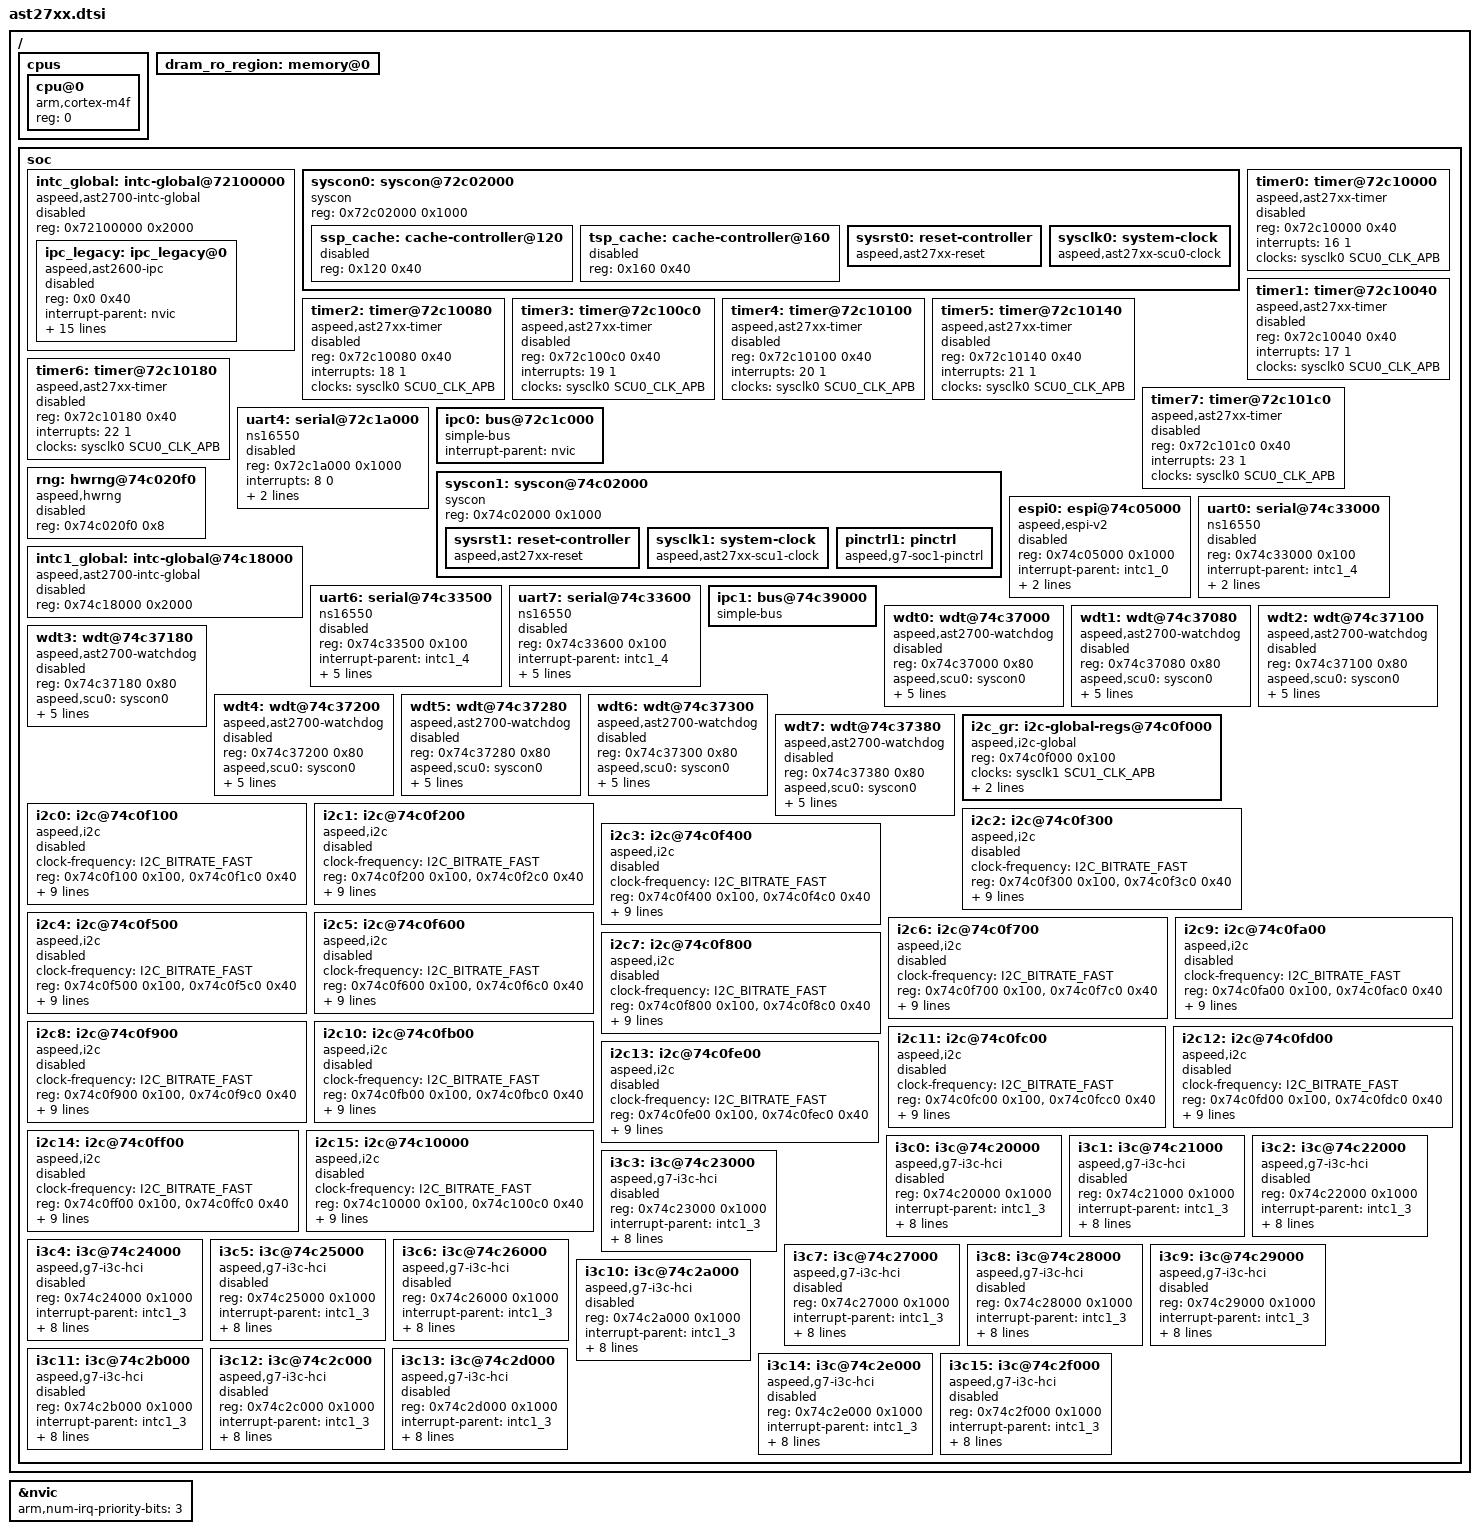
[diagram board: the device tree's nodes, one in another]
/*
 * SPDX-License-Identifier: Apache-2.0
 *
 * Copyright (c) 2023 ASPEED Technology Inc.
 */

#include <arm/armv7-m.dtsi>
#include <mem.h>
#include <aspeed/ast10x0-irq.h>
#include <zephyr/dt-bindings/clock/ast27xx_clock.h>
#include <zephyr/dt-bindings/reset/ast27xx_reset.h>
#include <zephyr/dt-bindings/i2c/i2c.h>
#include <zephyr/dt-bindings/pinctrl/ast27xx-soc1-pinctrl-groups.h>

/ {
	cpus {
		#address-cells = <1>;
		#size-cells = <0>;

		cpu@0 {
			device_type = "cpu";
			compatible = "arm,cortex-m4f";
			reg = <0>;
		};
	};

	dram_ro_region: memory@0 {
		device_type = "memory";
	};

	soc {
		intc_global: intc-global@72100000 {
			compatible = "aspeed,ast2700-intc-global", "syscon";
			reg = <0x72100000 0x2000>;
			#global-reg-cells = <2>;
			#address-cells = <1>;
			#size-cells = <1>;
			status = "disabled";

			ipc_legacy: ipc_legacy@0 {
				compatible = "aspeed,ast2600-ipc";
				reg = <0x0 0x40>;
				interrupt-parent = <&nvic>;
				interrupts = <144 AST10X0_IRQ_DEFAULT_PRIORITY>,
							 <145 AST10X0_IRQ_DEFAULT_PRIORITY>,
							 <146 AST10X0_IRQ_DEFAULT_PRIORITY>,
							 <147 AST10X0_IRQ_DEFAULT_PRIORITY>,
							 <148 AST10X0_IRQ_DEFAULT_PRIORITY>,
							 <149 AST10X0_IRQ_DEFAULT_PRIORITY>,
							 <150 AST10X0_IRQ_DEFAULT_PRIORITY>,
							 <151 AST10X0_IRQ_DEFAULT_PRIORITY>,
							 <152 AST10X0_IRQ_DEFAULT_PRIORITY>,
							 <153 AST10X0_IRQ_DEFAULT_PRIORITY>,
							 <154 AST10X0_IRQ_DEFAULT_PRIORITY>,
							 <155 AST10X0_IRQ_DEFAULT_PRIORITY>,
							 <156 AST10X0_IRQ_DEFAULT_PRIORITY>,
							 <157 AST10X0_IRQ_DEFAULT_PRIORITY>,
							 <158 AST10X0_IRQ_DEFAULT_PRIORITY>;
				status = "disabled";
			};
		};

		syscon0: syscon@72c02000 {
			compatible = "syscon";
			reg = <0x72c02000 0x1000>;
			#address-cells = <1>;
			#size-cells = <1>;
			ranges;

			ssp_cache: cache-controller@120 {
				reg = <0x120 0x40>;
				status = "disabled";
			};

			tsp_cache: cache-controller@160 {
				reg = <0x160 0x40>;
				status = "disabled";
			};

			sysrst0: reset-controller {
				compatible = "aspeed,ast27xx-reset";
				#reset-cells = <1>;
			};

			sysclk0: system-clock {
				compatible = "aspeed,ast27xx-scu0-clock";
				#clock-cells = <1>;
			};
		};

		timer0: timer@72c10000 {
			compatible = "aspeed,ast27xx-timer";
			reg = <0x72c10000 0x40>;
			interrupts = <16 1>;
			clocks = <&sysclk0 SCU0_CLK_APB>;
			status = "disabled";
		};

		timer1: timer@72c10040 {
			compatible = "aspeed,ast27xx-timer";
			reg = <0x72c10040 0x40>;
			interrupts = <17 1>;
			clocks = <&sysclk0 SCU0_CLK_APB>;
			status = "disabled";
		};

		timer2: timer@72c10080 {
			compatible = "aspeed,ast27xx-timer";
			reg = <0x72c10080 0x40>;
			interrupts = <18 1>;
			clocks = <&sysclk0 SCU0_CLK_APB>;
			status = "disabled";
		};

		timer3: timer@72c100c0 {
			compatible = "aspeed,ast27xx-timer";
			reg = <0x72c100c0 0x40>;
			interrupts = <19 1>;
			clocks = <&sysclk0 SCU0_CLK_APB>;
			status = "disabled";
		};

		timer4: timer@72c10100 {
			compatible = "aspeed,ast27xx-timer";
			reg = <0x72c10100 0x40>;
			interrupts = <20 1>;
			clocks = <&sysclk0 SCU0_CLK_APB>;
			status = "disabled";
		};

		timer5: timer@72c10140 {
			compatible = "aspeed,ast27xx-timer";
			reg = <0x72c10140 0x40>;
			interrupts = <21 1>;
			clocks = <&sysclk0 SCU0_CLK_APB>;
			status = "disabled";
		};

		timer6: timer@72c10180 {
			compatible = "aspeed,ast27xx-timer";
			reg = <0x72c10180 0x40>;
			interrupts = <22 1>;
			clocks = <&sysclk0 SCU0_CLK_APB>;
			status = "disabled";
		};

		timer7: timer@72c101c0 {
			compatible = "aspeed,ast27xx-timer";
			reg = <0x72c101c0 0x40>;
			interrupts = <23 1>;
			clocks = <&sysclk0 SCU0_CLK_APB>;
			status = "disabled";
		};

		uart4: serial@72c1a000 {
			compatible = "ns16550";
			reg = <0x72c1a000 0x1000>;
			interrupts = <8 0>;
			clocks = <&sysclk0 SCU0_CLK_GATE_UART4CLK>;
			status = "disabled";
			reg-shift = <2>;
		};

		ipc0: bus@72c1c000 {
			#address-cells = <1>;
			#size-cells = <1>;
			compatible = "simple-bus";
			interrupt-parent = <&nvic>;
			ranges = <0 0x72c1c000 0x1000>;
		};

		syscon1: syscon@74c02000 {
			compatible = "syscon";
			reg = <0x74c02000 0x1000>;
			#address-cells = <1>;
			#size-cells = <1>;
			ranges;

			sysrst1: reset-controller {
				compatible = "aspeed,ast27xx-reset";
				#reset-cells = <1>;
			};

			sysclk1: system-clock {
				compatible = "aspeed,ast27xx-scu1-clock";
				#clock-cells = <1>;
			};

			pinctrl1: pinctrl {
				compatible = "aspeed,g7-soc1-pinctrl";
			};
		};

		rng: hwrng@74c020f0 {
			compatible = "aspeed,hwrng";
			reg = <0x74c020f0 0x8>;
			status = "disabled";
		};

		espi0: espi@74c05000 {
			compatible = "aspeed,espi-v2";
			reg = <0x74c05000 0x1000>;
			interrupt-parent = <&intc1_0>;
			interrupts = <10 1>;
			clocks = <&sysclk1 SCU1_CLK_GATE_ESPI0CLK>;
			status = "disabled";
		};

		intc1_global: intc-global@74c18000 {
			compatible = "aspeed,ast2700-intc-global", "syscon";
			reg = <0x74c18000 0x2000>;
			#global-reg-cells = <2>;
			#address-cells = <1>;
			#size-cells = <1>;
			status = "disabled";
		};

		uart0: serial@74c33000 {
			compatible = "ns16550";
			reg = <0x74c33000 0x100>;
			interrupt-parent = <&intc1_4>;
			interrupts = <7 1>;
			status = "disabled";
			reg-shift = <2>;
		};

		uart6: serial@74c33500 {
			compatible = "ns16550";
			reg = <0x74c33500 0x100>;
			interrupt-parent = <&intc1_4>;
			interrupts = <12 1>;
			clocks = <&sysclk1 SCU1_CLK_GATE_UART6CLK>;
			resets = <&sysrst1 SCU1_RESET_UART6>;
			pinctrl-names = "default";
			pinctrl-0 = <pinctrl_uart6_default>;
			status = "disabled";
			reg-shift = <2>;
		};

		uart7: serial@74c33600 {
			compatible = "ns16550";
			reg = <0x74c33600 0x100>;
			interrupt-parent = <&intc1_4>;
			interrupts = <13 1>;
			clocks = <&sysclk1 SCU1_CLK_GATE_UART7CLK>;
			resets = <&sysrst1 SCU1_RESET_UART7>;
			pinctrl-names = "default";
			pinctrl-0 = <pinctrl_uart7_default>;
			status = "disabled";
			reg-shift = <2>;
		};

		ipc1: bus@74c39000 {
			#address-cells = <1>;
			#size-cells = <1>;
			compatible = "simple-bus";
			ranges = <0 0x74c39000 0x1000>;
		};

		wdt0: wdt@74c37000 {
			compatible = "aspeed,ast2700-watchdog";
			reg = <0x74c37000 0x80>;
			aspeed,scu0 = <&syscon0>;
			aspeed,scu1 = <&syscon1>;
			interrupt-parent = <&intc1_3>;
			interrupts = <16 1>;
			reset-mask = <0x8207ff79 0x000003f6 0x000093ec 0x40303803 0x00320000>;
			status = "disabled";
		};

		wdt1: wdt@74c37080 {
			compatible = "aspeed,ast2700-watchdog";
			reg = <0x74c37080 0x80>;
			aspeed,scu0 = <&syscon0>;
			aspeed,scu1 = <&syscon1>;
			interrupt-parent = <&intc1_3>;
			interrupts = <17 1>;
			reset-mask = <0x8207ff79 0x000003f6 0x000093ec 0x40303803 0x00320000>;
			status = "disabled";
		};

		wdt2: wdt@74c37100 {
			compatible = "aspeed,ast2700-watchdog";
			reg = <0x74c37100 0x80>;
			aspeed,scu0 = <&syscon0>;
			aspeed,scu1 = <&syscon1>;
			interrupt-parent = <&intc1_3>;
			interrupts = <18 1>;
			reset-mask = <0x8207ff79 0x000003f6 0x000093ec 0x40303803 0x00320000>;
			status = "disabled";
		};

		wdt3: wdt@74c37180 {
			compatible = "aspeed,ast2700-watchdog";
			reg = <0x74c37180 0x80>;
			aspeed,scu0 = <&syscon0>;
			aspeed,scu1 = <&syscon1>;
			interrupt-parent = <&intc1_3>;
			interrupts = <19 1>;
			reset-mask = <0x8207ff79 0x000003f6 0x000093ec 0x40303803 0x00320000>;
			status = "disabled";
		};

		wdt4: wdt@74c37200 {
			compatible = "aspeed,ast2700-watchdog";
			reg = <0x74c37200 0x80>;
			aspeed,scu0 = <&syscon0>;
			aspeed,scu1 = <&syscon1>;
			interrupt-parent = <&intc1_3>;
			interrupts = <20 1>;
			reset-mask = <0x8207ff79 0x000003f6 0x000093ec 0x40303803 0x00320000>;
			status = "disabled";
		};

		wdt5: wdt@74c37280 {
			compatible = "aspeed,ast2700-watchdog";
			reg = <0x74c37280 0x80>;
			aspeed,scu0 = <&syscon0>;
			aspeed,scu1 = <&syscon1>;
			interrupt-parent = <&intc1_3>;
			interrupts = <21 1>;
			reset-mask = <0x8207ff79 0x000003f6 0x000093ec 0x40303803 0x00320000>;
			status = "disabled";
		};

		wdt6: wdt@74c37300 {
			compatible = "aspeed,ast2700-watchdog";
			reg = <0x74c37300 0x80>;
			aspeed,scu0 = <&syscon0>;
			aspeed,scu1 = <&syscon1>;
			interrupt-parent = <&intc1_3>;
			interrupts = <22 1>;
			reset-mask = <0x8207ff79 0x000003f6 0x000093ec 0x40303803 0x00320000>;
			status = "disabled";
		};

		wdt7: wdt@74c37380 {
			compatible = "aspeed,ast2700-watchdog";
			reg = <0x74c37380 0x80>;
			aspeed,scu0 = <&syscon0>;
			aspeed,scu1 = <&syscon1>;
			interrupt-parent = <&intc1_3>;
			interrupts = <23 1>;
			reset-mask = <0x8207ff79 0x000003f6 0x000093ec 0x40303803 0x00320000>;
			status = "disabled";
		};

		i2c_gr: i2c-global-regs@74c0f000 {
			compatible = "aspeed,i2c-global";
			#address-cells = <1>;
			#size-cells = <0>;
			reg = <0x74c0f000 0x100>;
			clocks = <&sysclk1 SCU1_CLK_APB>;
			resets = <&sysrst1 SCU1_RESET_I2C>;
			clk-divider = <0xC6411208>;
		};

		i2c0: i2c@74c0f100 {
			compatible = "aspeed,i2c";
			clock-frequency = <I2C_BITRATE_FAST>;
			#address-cells = <1>;
			#size-cells = <0>;
			reg = <0x74c0f100 0x100>, <0x74c0f1c0 0x40>;
			interrupt-parent = <&intc1_2>;
			interrupts = <0 1>;
			clocks = <&sysclk1 SCU1_CLK_APB>;
			xfer-mode = "DMA";
			multi-master = <0>;
			smbus-timeout = <1>;
			manual-high-count = <0>;
			manual-low-count = <0>;
			manual-sda-delay = <0>;
			status = "disabled";
		};

		i2c1: i2c@74c0f200 {
			compatible = "aspeed,i2c";
			clock-frequency = <I2C_BITRATE_FAST>;
			#address-cells = <1>;
			#size-cells = <0>;
			reg = <0x74c0f200 0x100>, <0x74c0f2c0 0x40>;
			interrupt-parent = <&intc1_2>;
			interrupts = <1 1>;
			clocks = <&sysclk1 SCU1_CLK_APB>;
			xfer-mode = "DMA";
			multi-master = <0>;
			smbus-timeout = <1>;
			manual-high-count = <0>;
			manual-low-count = <0>;
			manual-sda-delay = <0>;
			status = "disabled";
		};

		i2c2: i2c@74c0f300 {
			compatible = "aspeed,i2c";
			clock-frequency = <I2C_BITRATE_FAST>;
			#address-cells = <1>;
			#size-cells = <0>;
			reg = <0x74c0f300 0x100>, <0x74c0f3c0 0x40>;
			interrupt-parent = <&intc1_2>;
			interrupts = <2 1>;
			clocks = <&sysclk1 SCU1_CLK_APB>;
			xfer-mode = "DMA";
			multi-master = <0>;
			smbus-timeout = <1>;
			manual-high-count = <0>;
			manual-low-count = <0>;
			manual-sda-delay = <0>;
			status = "disabled";
		};

		i2c3: i2c@74c0f400 {
			compatible = "aspeed,i2c";
			clock-frequency = <I2C_BITRATE_FAST>;
			#address-cells = <1>;
			#size-cells = <0>;
			reg = <0x74c0f400 0x100>, <0x74c0f4c0 0x40>;
			interrupt-parent = <&intc1_2>;
			interrupts = <3 1>;
			clocks = <&sysclk1 SCU1_CLK_APB>;
			xfer-mode = "DMA";
			multi-master = <0>;
			smbus-timeout = <1>;
			manual-high-count = <0>;
			manual-low-count = <0>;
			manual-sda-delay = <0>;
			status = "disabled";
		};

		i2c4: i2c@74c0f500 {
			compatible = "aspeed,i2c";
			clock-frequency = <I2C_BITRATE_FAST>;
			#address-cells = <1>;
			#size-cells = <0>;
			reg = <0x74c0f500 0x100>, <0x74c0f5c0 0x40>;
			interrupt-parent = <&intc1_2>;
			interrupts = <4 1>;
			clocks = <&sysclk1 SCU1_CLK_APB>;
			xfer-mode = "DMA";
			multi-master = <0>;
			smbus-timeout = <1>;
			manual-high-count = <0>;
			manual-low-count = <0>;
			manual-sda-delay = <0>;
			status = "disabled";
		};

		i2c5: i2c@74c0f600 {
			compatible = "aspeed,i2c";
			clock-frequency = <I2C_BITRATE_FAST>;
			#address-cells = <1>;
			#size-cells = <0>;
			reg = <0x74c0f600 0x100>, <0x74c0f6c0 0x40>;
			interrupt-parent = <&intc1_2>;
			interrupts = <5 1>;
			clocks = <&sysclk1 SCU1_CLK_APB>;
			xfer-mode = "DMA";
			multi-master = <0>;
			smbus-timeout = <1>;
			manual-high-count = <0>;
			manual-low-count = <0>;
			manual-sda-delay = <0>;
			status = "disabled";
		};

		i2c6: i2c@74c0f700 {
			compatible = "aspeed,i2c";
			clock-frequency = <I2C_BITRATE_FAST>;
			#address-cells = <1>;
			#size-cells = <0>;
			reg = <0x74c0f700 0x100>, <0x74c0f7c0 0x40>;
			interrupt-parent = <&intc1_2>;
			interrupts = <6 1>;
			clocks = <&sysclk1 SCU1_CLK_APB>;
			xfer-mode = "DMA";
			multi-master = <0>;
			smbus-timeout = <1>;
			manual-high-count = <0>;
			manual-low-count = <0>;
			manual-sda-delay = <0>;
			status = "disabled";
		};

		i2c7: i2c@74c0f800 {
			compatible = "aspeed,i2c";
			clock-frequency = <I2C_BITRATE_FAST>;
			#address-cells = <1>;
			#size-cells = <0>;
			reg = <0x74c0f800 0x100>, <0x74c0f8c0 0x40>;
			interrupt-parent = <&intc1_2>;
			interrupts = <7 1>;
			clocks = <&sysclk1 SCU1_CLK_APB>;
			xfer-mode = "DMA";
			multi-master = <0>;
			smbus-timeout = <1>;
			manual-high-count = <0>;
			manual-low-count = <0>;
			manual-sda-delay = <0>;
			status = "disabled";
		};

		i2c8: i2c@74c0f900 {
			compatible = "aspeed,i2c";
			clock-frequency = <I2C_BITRATE_FAST>;
			#address-cells = <1>;
			#size-cells = <0>;
			reg = <0x74c0f900 0x100>, <0x74c0f9c0 0x40>;
			interrupt-parent = <&intc1_2>;
			interrupts = <8 1>;
			clocks = <&sysclk1 SCU1_CLK_APB>;
			xfer-mode = "DMA";
			multi-master = <0>;
			smbus-timeout = <1>;
			manual-high-count = <0>;
			manual-low-count = <0>;
			manual-sda-delay = <0>;
			status = "disabled";
		};

		i2c9: i2c@74c0fa00 {
			compatible = "aspeed,i2c";
			clock-frequency = <I2C_BITRATE_FAST>;
			#address-cells = <1>;
			#size-cells = <0>;
			reg = <0x74c0fa00 0x100>, <0x74c0fac0 0x40>;
			interrupt-parent = <&intc1_2>;
			interrupts = <9 1>;
			clocks = <&sysclk1 SCU1_CLK_APB>;
			xfer-mode = "DMA";
			multi-master = <0>;
			smbus-timeout = <1>;
			manual-high-count = <0>;
			manual-low-count = <0>;
			manual-sda-delay = <0>;
			status = "disabled";
		};

		i2c10: i2c@74c0fb00 {
			compatible = "aspeed,i2c";
			clock-frequency = <I2C_BITRATE_FAST>;
			#address-cells = <1>;
			#size-cells = <0>;
			reg = <0x74c0fb00 0x100>, <0x74c0fbc0 0x40>;
			interrupt-parent = <&intc1_2>;
			interrupts = <10 1>;
			clocks = <&sysclk1 SCU1_CLK_APB>;
			xfer-mode = "DMA";
			multi-master = <0>;
			smbus-timeout = <1>;
			manual-high-count = <0>;
			manual-low-count = <0>;
			manual-sda-delay = <0>;
			status = "disabled";
		};

		i2c11: i2c@74c0fc00 {
			compatible = "aspeed,i2c";
			clock-frequency = <I2C_BITRATE_FAST>;
			#address-cells = <1>;
			#size-cells = <0>;
			reg = <0x74c0fc00 0x100>, <0x74c0fcc0 0x40>;
			interrupt-parent = <&intc1_2>;
			interrupts = <11 1>;
			clocks = <&sysclk1 SCU1_CLK_APB>;
			xfer-mode = "DMA";
			multi-master = <0>;
			smbus-timeout = <1>;
			manual-high-count = <0>;
			manual-low-count = <0>;
			manual-sda-delay = <0>;
			status = "disabled";
		};

		i2c12: i2c@74c0fd00 {
			compatible = "aspeed,i2c";
			clock-frequency = <I2C_BITRATE_FAST>;
			#address-cells = <1>;
			#size-cells = <0>;
			reg = <0x74c0fd00 0x100>, <0x74c0fdc0 0x40>;
			interrupt-parent = <&intc1_2>;
			interrupts = <12 1>;
			clocks = <&sysclk1 SCU1_CLK_APB>;
			xfer-mode = "DMA";
			multi-master = <0>;
			smbus-timeout = <1>;
			manual-high-count = <0>;
			manual-low-count = <0>;
			manual-sda-delay = <0>;
			status = "disabled";
		};

		i2c13: i2c@74c0fe00 {
			compatible = "aspeed,i2c";
			clock-frequency = <I2C_BITRATE_FAST>;
			#address-cells = <1>;
			#size-cells = <0>;
			reg = <0x74c0fe00 0x100>, <0x74c0fec0 0x40>;
			interrupt-parent = <&intc1_2>;
			interrupts = <13 1>;
			clocks = <&sysclk1 SCU1_CLK_APB>;
			xfer-mode = "DMA";
			multi-master = <0>;
			smbus-timeout = <1>;
			manual-high-count = <0>;
			manual-low-count = <0>;
			manual-sda-delay = <0>;
			status = "disabled";
		};

		i2c14: i2c@74c0ff00 {
			compatible = "aspeed,i2c";
			clock-frequency = <I2C_BITRATE_FAST>;
			#address-cells = <1>;
			#size-cells = <0>;
			reg = <0x74c0ff00 0x100>, <0x74c0ffc0 0x40>;
			interrupt-parent = <&intc1_2>;
			interrupts = <14 1>;
			clocks = <&sysclk1 SCU1_CLK_APB>;
			xfer-mode = "DMA";
			multi-master = <0>;
			smbus-timeout = <1>;
			manual-high-count = <0>;
			manual-low-count = <0>;
			manual-sda-delay = <0>;
			status = "disabled";
		};

		i2c15: i2c@74c10000 {
			compatible = "aspeed,i2c";
			clock-frequency = <I2C_BITRATE_FAST>;
			#address-cells = <1>;
			#size-cells = <0>;
			reg = <0x74c10000 0x100>, <0x74c100c0 0x40>;
			interrupt-parent = <&intc1_2>;
			interrupts = <15 1>;
			clocks = <&sysclk1 SCU1_CLK_APB>;
			xfer-mode = "DMA";
			multi-master = <0>;
			smbus-timeout = <1>;
			manual-high-count = <0>;
			manual-low-count = <0>;
			manual-sda-delay = <0>;
			status = "disabled";
		};

		i3c0: i3c@74c20000 {
			compatible = "aspeed,g7-i3c-hci";
			reg = <0x74c20000 0x1000>;
			interrupt-parent = <&intc1_3>;
			interrupts = <0 1>;
			clocks = <&sysclk1 SCU1_CLK_GATE_I3C0CLK>;
			resets = <&sysrst1 SCU1_RESET_I3C0>, <&sysrst1 SCU1_RESET_I3CDMA>;
			reset-names = "core", "dma";
			i2c-scl-hz = <1000000>;
			i3c-scl-hz = <12500000>;
			io-mode = "pio";
			pinctrl-names = "default";
			pinctrl-0 = <pinctrl_i3c0_default>;
			status = "disabled";
			#address-cells = <3>;
			#size-cells = <0>;
		};

		i3c1: i3c@74c21000 {
			compatible = "aspeed,g7-i3c-hci";
			reg = <0x74c21000 0x1000>;
			interrupt-parent = <&intc1_3>;
			interrupts = <1 1>;
			clocks = <&sysclk1 SCU1_CLK_GATE_I3C1CLK>;
			resets = <&sysrst1 SCU1_RESET_I3C1>, <&sysrst1 SCU1_RESET_I3CDMA>;
			reset-names = "core", "dma";
			i2c-scl-hz = <1000000>;
			i3c-scl-hz = <12500000>;
			io-mode = "pio";
			pinctrl-names = "default";
			pinctrl-0 = <pinctrl_i3c1_default>;
			status = "disabled";
			#address-cells = <3>;
			#size-cells = <0>;
		};

		i3c2: i3c@74c22000 {
			compatible = "aspeed,g7-i3c-hci";
			reg = <0x74c22000 0x1000>;
			interrupt-parent = <&intc1_3>;
			interrupts = <2 1>;
			clocks = <&sysclk1 SCU1_CLK_GATE_I3C2CLK>;
			resets = <&sysrst1 SCU1_RESET_I3C2>, <&sysrst1 SCU1_RESET_I3CDMA>;
			reset-names = "core", "dma";
			i2c-scl-hz = <1000000>;
			i3c-scl-hz = <12500000>;
			io-mode = "pio";
			pinctrl-names = "default";
			pinctrl-0 = <pinctrl_i3c2_default>;
			status = "disabled";
			#address-cells = <3>;
			#size-cells = <0>;
		};

		i3c3: i3c@74c23000 {
			compatible = "aspeed,g7-i3c-hci";
			reg = <0x74c23000 0x1000>;
			interrupt-parent = <&intc1_3>;
			interrupts = <3 1>;
			clocks = <&sysclk1 SCU1_CLK_GATE_I3C3CLK>;
			resets = <&sysrst1 SCU1_RESET_I3C3>, <&sysrst1 SCU1_RESET_I3CDMA>;
			reset-names = "core", "dma";
			i2c-scl-hz = <1000000>;
			i3c-scl-hz = <12500000>;
			io-mode = "pio";
			pinctrl-names = "default";
			pinctrl-0 = <pinctrl_i3c3_default>;
			status = "disabled";
			#address-cells = <3>;
			#size-cells = <0>;
		};

		i3c4: i3c@74c24000 {
			compatible = "aspeed,g7-i3c-hci";
			reg = <0x74c24000 0x1000>;
			interrupt-parent = <&intc1_3>;
			interrupts = <4 1>;
			clocks = <&sysclk1 SCU1_CLK_GATE_I3C4CLK>;
			resets = <&sysrst1 SCU1_RESET_I3C4>, <&sysrst1 SCU1_RESET_I3CDMA>;
			reset-names = "core", "dma";
			i2c-scl-hz = <1000000>;
			i3c-scl-hz = <12500000>;
			io-mode = "pio";
			pinctrl-names = "default";
			pinctrl-0 = <pinctrl_i3c4_default>;
			status = "disabled";
			#address-cells = <3>;
			#size-cells = <0>;
		};

		i3c5: i3c@74c25000 {
			compatible = "aspeed,g7-i3c-hci";
			reg = <0x74c25000 0x1000>;
			interrupt-parent = <&intc1_3>;
			interrupts = <5 1>;
			clocks = <&sysclk1 SCU1_CLK_GATE_I3C5CLK>;
			resets = <&sysrst1 SCU1_RESET_I3C5>, <&sysrst1 SCU1_RESET_I3CDMA>;
			reset-names = "core", "dma";
			i2c-scl-hz = <1000000>;
			i3c-scl-hz = <12500000>;
			io-mode = "pio";
			pinctrl-names = "default";
			pinctrl-0 = <pinctrl_i3c5_default>;
			status = "disabled";
			#address-cells = <3>;
			#size-cells = <0>;
		};

		i3c6: i3c@74c26000 {
			compatible = "aspeed,g7-i3c-hci";
			reg = <0x74c26000 0x1000>;
			interrupt-parent = <&intc1_3>;
			interrupts = <6 1>;
			clocks = <&sysclk1 SCU1_CLK_GATE_I3C6CLK>;
			resets = <&sysrst1 SCU1_RESET_I3C6>, <&sysrst1 SCU1_RESET_I3CDMA>;
			reset-names = "core", "dma";
			i2c-scl-hz = <1000000>;
			i3c-scl-hz = <12500000>;
			io-mode = "pio";
			pinctrl-names = "default";
			pinctrl-0 = <pinctrl_i3c6_default>;
			status = "disabled";
			#address-cells = <3>;
			#size-cells = <0>;
		};

		i3c7: i3c@74c27000 {
			compatible = "aspeed,g7-i3c-hci";
			reg = <0x74c27000 0x1000>;
			interrupt-parent = <&intc1_3>;
			interrupts = <7 1>;
			clocks = <&sysclk1 SCU1_CLK_GATE_I3C7CLK>;
			resets = <&sysrst1 SCU1_RESET_I3C7>, <&sysrst1 SCU1_RESET_I3CDMA>;
			reset-names = "core", "dma";
			i2c-scl-hz = <1000000>;
			i3c-scl-hz = <12500000>;
			io-mode = "pio";
			pinctrl-names = "default";
			pinctrl-0 = <pinctrl_i3c7_default>;
			status = "disabled";
			#address-cells = <3>;
			#size-cells = <0>;
		};

		i3c8: i3c@74c28000 {
			compatible = "aspeed,g7-i3c-hci";
			reg = <0x74c28000 0x1000>;
			interrupt-parent = <&intc1_3>;
			interrupts = <8 1>;
			clocks = <&sysclk1 SCU1_CLK_GATE_I3C8CLK>;
			resets = <&sysrst1 SCU1_RESET_I3C8>, <&sysrst1 SCU1_RESET_I3CDMA>;
			reset-names = "core", "dma";
			i2c-scl-hz = <1000000>;
			i3c-scl-hz = <12500000>;
			io-mode = "pio";
			pinctrl-names = "default";
			pinctrl-0 = <pinctrl_i3c8_default>;
			status = "disabled";
			#address-cells = <3>;
			#size-cells = <0>;
		};

		i3c9: i3c@74c29000 {
			compatible = "aspeed,g7-i3c-hci";
			reg = <0x74c29000 0x1000>;
			interrupt-parent = <&intc1_3>;
			interrupts = <9 1>;
			clocks = <&sysclk1 SCU1_CLK_GATE_I3C9CLK>;
			resets = <&sysrst1 SCU1_RESET_I3C9>, <&sysrst1 SCU1_RESET_I3CDMA>;
			reset-names = "core", "dma";
			i2c-scl-hz = <1000000>;
			i3c-scl-hz = <12500000>;
			io-mode = "pio";
			pinctrl-names = "default";
			pinctrl-0 = <pinctrl_i3c9_default>;
			status = "disabled";
			#address-cells = <3>;
			#size-cells = <0>;
		};

		i3c10: i3c@74c2a000 {
			compatible = "aspeed,g7-i3c-hci";
			reg = <0x74c2a000 0x1000>;
			interrupt-parent = <&intc1_3>;
			interrupts = <10 1>;
			clocks = <&sysclk1 SCU1_CLK_GATE_I3C10CLK>;
			resets = <&sysrst1 SCU1_RESET_I3C10>, <&sysrst1 SCU1_RESET_I3CDMA>;
			reset-names = "core", "dma";
			i2c-scl-hz = <1000000>;
			i3c-scl-hz = <12500000>;
			io-mode = "pio";
			pinctrl-names = "default";
			pinctrl-0 = <pinctrl_i3c10_default>;
			status = "disabled";
			#address-cells = <3>;
			#size-cells = <0>;
		};

		i3c11: i3c@74c2b000 {
			compatible = "aspeed,g7-i3c-hci";
			reg = <0x74c2b000 0x1000>;
			interrupt-parent = <&intc1_3>;
			interrupts = <11 1>;
			clocks = <&sysclk1 SCU1_CLK_GATE_I3C11CLK>;
			resets = <&sysrst1 SCU1_RESET_I3C11>, <&sysrst1 SCU1_RESET_I3CDMA>;
			reset-names = "core", "dma";
			i2c-scl-hz = <1000000>;
			i3c-scl-hz = <12500000>;
			io-mode = "pio";
			pinctrl-names = "default";
			pinctrl-0 = <pinctrl_i3c11_default>;
			status = "disabled";
			#address-cells = <3>;
			#size-cells = <0>;
		};

		i3c12: i3c@74c2c000 {
			compatible = "aspeed,g7-i3c-hci";
			reg = <0x74c2c000 0x1000>;
			interrupt-parent = <&intc1_3>;
			interrupts = <12 1>;
			clocks = <&sysclk1 SCU1_CLK_GATE_I3C12CLK>;
			resets = <&sysrst1 SCU1_RESET_I3C12>, <&sysrst1 SCU1_RESET_I3CDMA>;
			reset-names = "core", "dma";
			i2c-scl-hz = <1000000>;
			i3c-scl-hz = <12500000>;
			io-mode = "pio";
			pinctrl-names = "default";
			pinctrl-0 = <pinctrl_i3c12_default>;
			status = "disabled";
			#address-cells = <3>;
			#size-cells = <0>;
		};

		i3c13: i3c@74c2d000 {
			compatible = "aspeed,g7-i3c-hci";
			reg = <0x74c2d000 0x1000>;
			interrupt-parent = <&intc1_3>;
			interrupts = <13 1>;
			clocks = <&sysclk1 SCU1_CLK_GATE_I3C13CLK>;
			resets = <&sysrst1 SCU1_RESET_I3C13>, <&sysrst1 SCU1_RESET_I3CDMA>;
			reset-names = "core", "dma";
			i2c-scl-hz = <1000000>;
			i3c-scl-hz = <12500000>;
			io-mode = "pio";
			pinctrl-names = "default";
			pinctrl-0 = <pinctrl_i3c13_default>;
			status = "disabled";
			#address-cells = <3>;
			#size-cells = <0>;
		};

		i3c14: i3c@74c2e000 {
			compatible = "aspeed,g7-i3c-hci";
			reg = <0x74c2e000 0x1000>;
			interrupt-parent = <&intc1_3>;
			interrupts = <14 1>;
			clocks = <&sysclk1 SCU1_CLK_GATE_I3C14CLK>;
			resets = <&sysrst1 SCU1_RESET_I3C14>, <&sysrst1 SCU1_RESET_I3CDMA>;
			reset-names = "core", "dma";
			i2c-scl-hz = <1000000>;
			i3c-scl-hz = <12500000>;
			io-mode = "pio";
			pinctrl-names = "default";
			pinctrl-0 = <pinctrl_i3c14_default>;
			status = "disabled";
			#address-cells = <3>;
			#size-cells = <0>;
		};

		i3c15: i3c@74c2f000 {
			compatible = "aspeed,g7-i3c-hci";
			reg = <0x74c2f000 0x1000>;
			interrupt-parent = <&intc1_3>;
			interrupts = <15 1>;
			clocks = <&sysclk1 SCU1_CLK_GATE_I3C15CLK>;
			resets = <&sysrst1 SCU1_RESET_I3C15>, <&sysrst1 SCU1_RESET_I3CDMA>;
			reset-names = "core", "dma";
			i2c-scl-hz = <1000000>;
			i3c-scl-hz = <12500000>;
			io-mode = "pio";
			pinctrl-names = "default";
			pinctrl-0 = <pinctrl_i3c15_default>;
			status = "disabled";
			#address-cells = <3>;
			#size-cells = <0>;
		};
	};
};

&nvic {
	arm,num-irq-priority-bits = <3>;
};

#include "ast27xx-pinctrl.dtsi"
